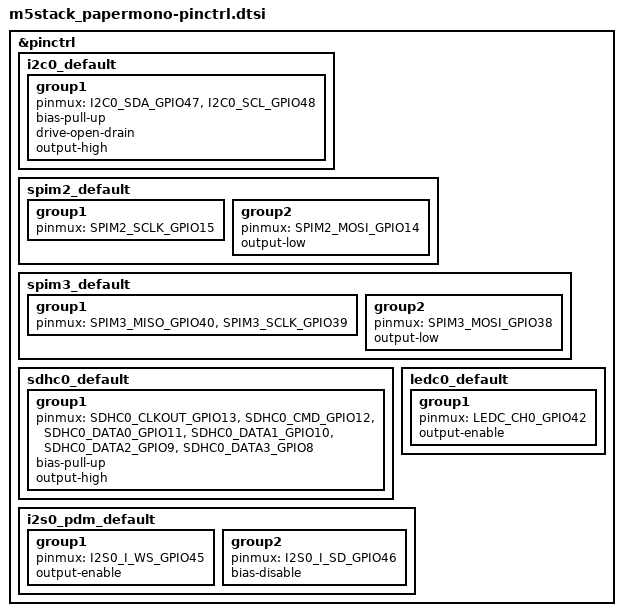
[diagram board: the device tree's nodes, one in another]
/* SPDX-License-Identifier: MIT */

#include <zephyr/dt-bindings/pinctrl/esp-pinctrl-common.h>
#include <zephyr/dt-bindings/pinctrl/esp32s3-pinctrl.h>
#include <zephyr/dt-bindings/pinctrl/esp32s3-gpio-sigmap.h>

&pinctrl {
	i2c0_default: i2c0_default {
		group1 {
			pinmux = <I2C0_SDA_GPIO47>,
				 <I2C0_SCL_GPIO48>;
			bias-pull-up;
			drive-open-drain;
			output-high;
		};
	};

	spim2_default: spim2_default {
		group1 {
			pinmux = <SPIM2_SCLK_GPIO15>;
		};

		group2 {
			pinmux = <SPIM2_MOSI_GPIO14>;
			output-low;
		};
	};

	spim3_default: spim3_default {
		group1 {
			pinmux = <SPIM3_MISO_GPIO40>,
				 <SPIM3_SCLK_GPIO39>;
		};

		group2 {
			pinmux = <SPIM3_MOSI_GPIO38>;
			output-low;
		};
	};

	sdhc0_default: sdhc0_default {
		group1 {
			/* CLK is GPIO13 and CMD is GPIO12 on this board. These two
			 * were swapped here, which is why the TF card never
			 * responded: the card received no clock and every command
			 * timed out at the host controller, so card initialisation
			 * failed with -ENOTSUP ("unknown card type") and all
			 * content features stayed disabled.
			 *
			 * Matches M5Stack's M5PaperMono-UserDemo
			 * (main/hal/hal_tf_card.cpp): TF_CLK_PIN = GPIO13,
			 * TF_CMD_PIN = GPIO12, D0..D3 = GPIO11..8.
			 */
			pinmux = <SDHC0_CLKOUT_GPIO13>,
				 <SDHC0_CMD_GPIO12>,
				 <SDHC0_DATA0_GPIO11>,
				 <SDHC0_DATA1_GPIO10>,
				 <SDHC0_DATA2_GPIO9>,
				 <SDHC0_DATA3_GPIO8>;
			bias-pull-up;
			output-high;
		};
	};

	ledc0_default: ledc0_default {
		group1 {
			pinmux = <LEDC_CH0_GPIO42>;
			output-enable;
		};
	};

	i2s0_pdm_default: i2s0_pdm_default {
		group1 {
			pinmux = <I2S0_I_WS_GPIO45>;
			output-enable;
		};

		group2 {
			pinmux = <I2S0_I_SD_GPIO46>;
			bias-disable;
		};
	};
};
